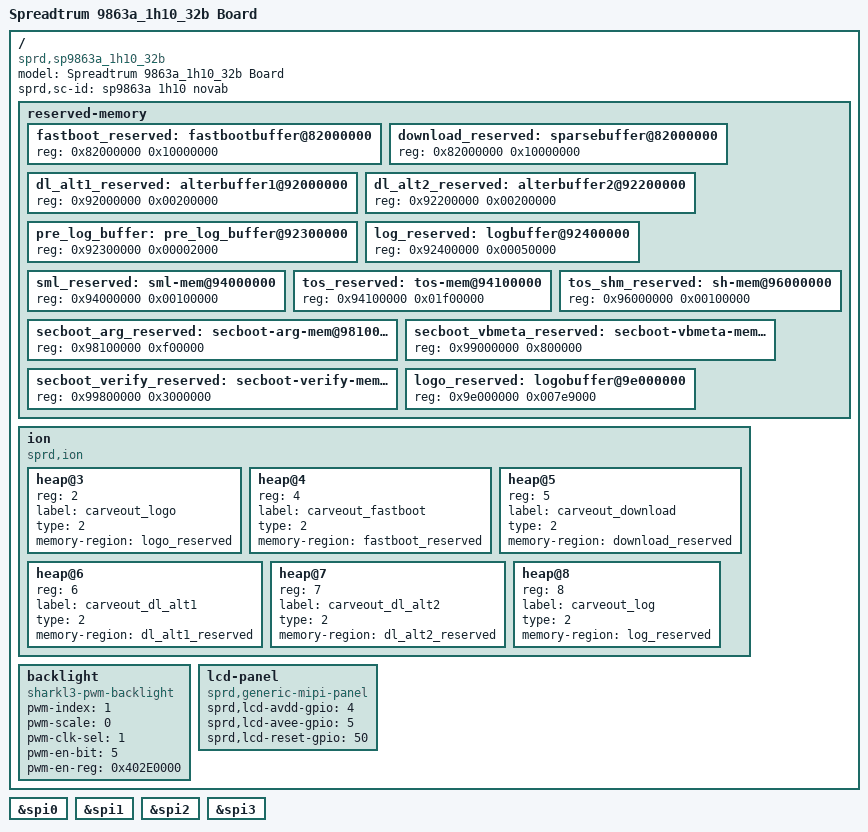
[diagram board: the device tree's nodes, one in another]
/*
 * Spreadtrum SP9860g board DTS file
 *
 * Copyright (C) 2016, Spreadtrum Communications Inc.
 *
 * This file is licensed under a dual GPLv2 or X11 license.
 */

/dts-v1/;

#include "sc9863a.dtsi"
#include "sharkl3.dtsi"
#include "sc2721.dtsi"
#include "lcd/lcd_nt35596_boe_mipi_fhd.dtsi"
#include "lcd/lcd_nt35532_truly_mipi_fhd.dtsi"
#include "lcd/lcd_nt35695_truly_mipi_fhd.dtsi"
#include "lcd/lcd_dummy_mipi.dtsi"

/ {
	model = "Spreadtrum 9863a_1h10_32b Board";

	compatible = "sprd,sp9863a_1h10_32b";

	sprd,sc-id = "sp9863a 1h10 novab";

	reserved-memory {
		#address-cells = <1>;
		#size-cells = <1>;
		ranges;

		fastboot_reserved: fastbootbuffer@82000000{
			reg = <0x82000000 0x10000000>;
		};

		download_reserved: sparsebuffer@82000000{
			reg = <0x82000000 0x10000000>;
		};

		dl_alt1_reserved: alterbuffer1@92000000{
			reg = <0x92000000 0x00200000>;
		};

		dl_alt2_reserved: alterbuffer2@92200000{
			reg = <0x92200000 0x00200000>;
		};

		pre_log_buffer: pre_log_buffer@92300000{
			reg = <0x92300000 0x00002000>;
		};

		log_reserved: logbuffer@92400000{
			reg = <0x92400000 0x00050000>;
		};

		/* must be 4K aligned */
		sml_reserved: sml-mem@94000000{
			reg = <0x94000000 0x00100000>;
		};

		tos_reserved: tos-mem@94100000{
			reg = <0x94100000 0x01f00000>;
		};

		tos_shm_reserved: sh-mem@96000000{
			reg = <0x96000000 0x00100000>;
		};

		secboot_arg_reserved: secboot-arg-mem@98100000{
			reg = <0x98100000 0xf00000>;
		};

		secboot_vbmeta_reserved: secboot-vbmeta-mem@99000000{
			reg = <0x99000000 0x800000>;
		};

		secboot_verify_reserved: secboot-verify-mem@99800000{
			reg = <0x99800000 0x3000000>;
		};

		/* 1080x1920x4Bytes */
		logo_reserved: logobuffer@9e000000{
			reg = <0x9e000000 0x007e9000>;
		};
	};

	ion {
		compatible = "sprd,ion";
		#address-cells = <1>;
		#size-cells = <0>;

		heap@3 {
			reg = <2>;
			label = "carveout_logo";
			type = <2>;
			memory-region = <&logo_reserved>;
		};

		heap@4 {
			reg = <4>;
			label = "carveout_fastboot";
			type = <2>;
			memory-region = <&fastboot_reserved>;
		};

		heap@5 {
			reg = <5>;
			label = "carveout_download";
			type = <2>;
			memory-region = <&download_reserved>;
		};

		heap@6 {
			reg = <6>;
			label = "carveout_dl_alt1";
			type = <2>;
			memory-region = <&dl_alt1_reserved>;
		};

		heap@7 {
			reg = <7>;
			label = "carveout_dl_alt2";
			type = <2>;
			memory-region = <&dl_alt2_reserved>;
		};

		heap@8 {
			reg = <8>;
			label = "carveout_log";
			type = <2>;
			memory-region = <&log_reserved>;
		};
	};

	backlight {
		compatible = "sharkl3-pwm-backlight";
		pwm-index = <1>;
		pwm-scale = <0>;
		pwm-clk-sel = <1>;
		pwm-en-bit = <5>;
		pwm-en-reg = <0x402E0000>;
	};

	lcd-panel {
		compatible = "sprd,generic-mipi-panel";
		sprd,lcd-avdd-gpio = <4>;
		sprd,lcd-avee-gpio = <5>;
		sprd,lcd-reset-gpio = <50>;
	};
};

&spi0 {
	status = "okay";
};
&spi1 {
	status = "okay";
};
&spi2 {
	status = "okay";
};
&spi3 {
	status = "okay";
};
